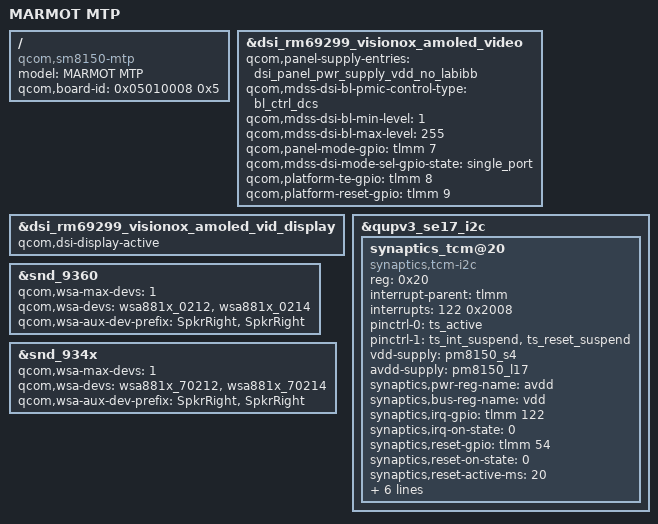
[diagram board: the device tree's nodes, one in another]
/* Copyright (c) 2020, The Linux Foundation. All rights reserved.
 *
 * This program is free software; you can redistribute it and/or modify
 * it under the terms of the GNU General Public License version 2 and
 * only version 2 as published by the Free Software Foundation.
 *
 * This program is distributed in the hope that it will be useful,
 * but WITHOUT ANY WARRANTY; without even the implied warranty of
 * MERCHANTABILITY or FITNESS FOR A PARTICULAR PURPOSE.  See the
 * GNU General Public License for more details.
 */

/dts-v1/;
/plugin/;

#include <dt-bindings/clock/qcom,camcc-sm8150.h>

#include "sm8150-mtp.dtsi"

#include "sdx5xm-external-soc.dtsi"
#include "sm8150-marmot.dtsi"

/ {
	model = "MARMOT MTP";
	compatible = "qcom,sm8150-mtp", "qcom,sm8150", "qcom,mtp";
	qcom,board-id = <0x05010008 0x5>;
};

&dsi_rm69299_visionox_amoled_video {
	qcom,panel-supply-entries = <&dsi_panel_pwr_supply_vdd_no_labibb>;
	qcom,mdss-dsi-bl-pmic-control-type = "bl_ctrl_dcs";
	qcom,mdss-dsi-bl-min-level = <1>;
	qcom,mdss-dsi-bl-max-level = <255>;
	qcom,panel-mode-gpio = <&tlmm 7 0>;
	qcom,mdss-dsi-mode-sel-gpio-state = "single_port";
	qcom,platform-te-gpio = <&tlmm 8 0>;
	qcom,platform-reset-gpio = <&tlmm 9 0>;
};

&dsi_rm69299_visionox_amoled_vid_display {
	qcom,dsi-display-active;
};

&qupv3_se17_i2c {
	status = "ok";

	synaptics_tcm@20 {
		compatible = "synaptics,tcm-i2c";
		reg = <0x20>;
		interrupt-parent = <&tlmm>;
		interrupts = <122 0x2008>;
		pinctrl-names = "pmx_ts_active","pmx_ts_suspend";
		pinctrl-0 = <&ts_active>;
		pinctrl-1 = <&ts_int_suspend &ts_reset_suspend>;
		vdd-supply = <&pm8150_s4>;
		avdd-supply = <&pm8150_l17>;
		synaptics,pwr-reg-name = "avdd";
		synaptics,bus-reg-name = "vdd";
		synaptics,irq-gpio = <&tlmm 122 0x2008>;
		synaptics,irq-on-state = <0>;
		synaptics,reset-gpio = <&tlmm 54 0x00>;
		synaptics,reset-on-state = <0>;
		synaptics,reset-active-ms = <20>;
		synaptics,reset-delay-ms = <200>;
		synaptics,power-delay-ms = <200>;
		synaptics,ubl-i2c-addr = <0x20>;
		synaptics,extend_report;
		synaptics,firmware-name = "synaptics_firmware.img";
	};
};

&snd_9360 {
	qcom,wsa-max-devs = <1>;
	qcom,wsa-devs = <&wsa881x_0212>, <&wsa881x_0214>;
	qcom,wsa-aux-dev-prefix = "SpkrRight", "SpkrRight";
};

&snd_934x {
	qcom,wsa-max-devs = <1>;
	qcom,wsa-devs = <&wsa881x_70212>, <&wsa881x_70214>;
	qcom,wsa-aux-dev-prefix = "SpkrRight", "SpkrRight";
};
